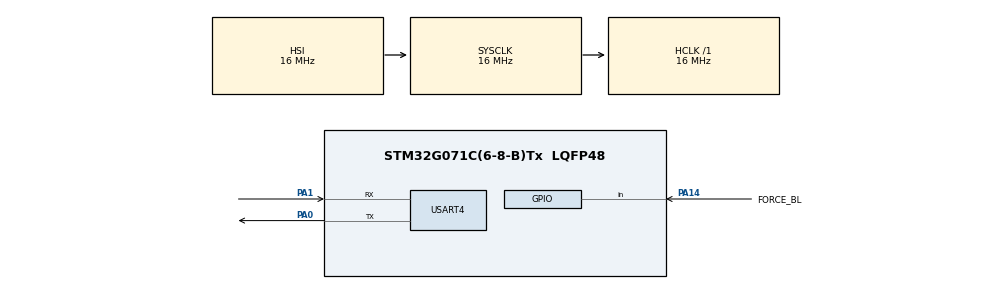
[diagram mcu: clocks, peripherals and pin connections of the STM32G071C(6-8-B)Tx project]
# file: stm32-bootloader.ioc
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Mcu.Family=STM32G0
Mcu.Name=STM32G071C(6-8-B)Tx
Mcu.Package=LQFP48
PA0.Mode=Asynchronous
PA0.Signal=USART4_TX
PA1.Mode=Asynchronous
PA1.Signal=USART4_RX
PA14-BOOT0.GPIO_Label=FORCE_BL
PA14-BOOT0.GPIO_PuPd=GPIO_PULLDOWN
PA14-BOOT0.Signal=GPIO_Input
ProjectManager.HeapSize=0x200
ProjectManager.StackSize=0x400
ProjectManager.TargetToolchain=STM32CubeIDE
RCC.AHBFreq_Value=16000000
RCC.CortexFreq_Value=16000000
RCC.EXTERNAL_CLOCK_VALUE=48000
RCC.HCLKFreq_Value=16000000
RCC.HSE_VALUE=8000000
RCC.HSI_VALUE=16000000
RCC.LSE_VALUE=32768
RCC.SYSCLKFreq_VALUE=16000000
RCC.VCOOutputFreq_Value=128000000
USART4.Parity=PARITY_EVEN
USART4.StopBits=STOPBITS_1
USART4.VirtualMode-Asynchronous=VM_ASYNC
USART4.WordLength=WORDLENGTH_9B
VP_SYS_VS_DBSignals.Mode=DisableDeadBatterySignals
board=custom

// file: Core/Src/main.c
/* USER CODE BEGIN Header */
/**
 ******************************************************************************
 * @file           : main.c
 * @brief          : Main program body
 ******************************************************************************
 * @attention
 *
 * Copyright (c) 2022 STMicroelectronics.
 * All rights reserved.
 *
 * This software is licensed under terms that can be found in the LICENSE file
 * in the root directory of this software component.
 * If no LICENSE file comes with this software, it is provided AS-IS.
 *
 ******************************************************************************
 */
/* USER CODE END Header */
#include "main.h"

/* USER CODE BEGIN Includes */
#include "bootloader.h"

/* USER CODE END Includes */

void SystemClock_Config(void);
static void MX_GPIO_Init(void);
static void MX_USART4_UART_Init(void);
/* USER CODE BEGIN PFP */
static void MX_GPIO_DeInit(void);
/* USER CODE END PFP */

int main(void) {

  /* MCU Configuration--------------------------------------------------------*/

  /* Reset of all peripherals, Initializes the Flash interface and the Systick. */
  HAL_Init();

  /* Configure the system clock */
  SystemClock_Config();

  /* USER CODE BEGIN SysInit */
  uwTick = 0;
  while (HAL_GetTick() < 300)
    ;

  /* USER CODE END SysInit */

  /* Initialize all configured peripherals */
  MX_GPIO_Init();

  /* USER CODE BEGIN 2 */

  uint8_t bl_forced = LL_GPIO_IsInputPinSet(FORCE_BL_GPIO_Port, FORCE_BL_Pin);
  MX_GPIO_DeInit();

  /* USER CODE END 2 */

  /* Infinite loop */
  /* USER CODE BEGIN WHILE */
  if (bl_forced == 0) {
    MX_USART4_UART_Init();
    bootloader_loop(USART4);
  }

  bootloader_start_user_program();

  /* USER CODE END WHILE */

}

void SystemClock_Config(void) {
  RCC_OscInitTypeDef RCC_OscInitStruct = { 0 };
  RCC_ClkInitTypeDef RCC_ClkInitStruct = { 0 };

  /** Configure the main internal regulator output voltage
   */
  HAL_PWREx_ControlVoltageScaling(PWR_REGULATOR_VOLTAGE_SCALE1);
  /** Initializes the RCC Oscillators according to the specified parameters
   * in the RCC_OscInitTypeDef structure.
   */
  RCC_OscInitStruct.OscillatorType = RCC_OSCILLATORTYPE_HSI;
  RCC_OscInitStruct.HSIState = RCC_HSI_ON;
  RCC_OscInitStruct.HSIDiv = RCC_HSI_DIV1;
  RCC_OscInitStruct.HSICalibrationValue = RCC_HSICALIBRATION_DEFAULT;
  RCC_OscInitStruct.PLL.PLLState = RCC_PLL_NONE;
  if (HAL_RCC_OscConfig(&RCC_OscInitStruct) != HAL_OK) {
    Error_Handler();
  }
  /** Initializes the CPU, AHB and APB buses clocks
   */
  RCC_ClkInitStruct.ClockType = RCC_CLOCKTYPE_HCLK | RCC_CLOCKTYPE_SYSCLK | RCC_CLOCKTYPE_PCLK1;
  RCC_ClkInitStruct.SYSCLKSource = RCC_SYSCLKSOURCE_HSI;
  RCC_ClkInitStruct.AHBCLKDivider = RCC_SYSCLK_DIV1;
  RCC_ClkInitStruct.APB1CLKDivider = RCC_HCLK_DIV1;

  if (HAL_RCC_ClockConfig(&RCC_ClkInitStruct, FLASH_LATENCY_0) != HAL_OK) {
    Error_Handler();
  }
}

static void MX_USART4_UART_Init(void) {

  LL_USART_InitTypeDef USART_InitStruct = { 0 };

  LL_GPIO_InitTypeDef GPIO_InitStruct = { 0 };

  /* Peripheral clock enable */
  LL_APB1_GRP1_EnableClock(LL_APB1_GRP1_PERIPH_USART4);

  LL_IOP_GRP1_EnableClock(LL_IOP_GRP1_PERIPH_GPIOA);
  /**USART4 GPIO Configuration
   PA0   ------> USART4_TX
   PA1   ------> USART4_RX
   */
  GPIO_InitStruct.Pin = LL_GPIO_PIN_0;
  GPIO_InitStruct.Mode = LL_GPIO_MODE_ALTERNATE;
  GPIO_InitStruct.Speed = LL_GPIO_SPEED_FREQ_LOW;
  GPIO_InitStruct.OutputType = LL_GPIO_OUTPUT_PUSHPULL;
  GPIO_InitStruct.Pull = LL_GPIO_PULL_NO;
  GPIO_InitStruct.Alternate = LL_GPIO_AF_4;
  LL_GPIO_Init(GPIOA, &GPIO_InitStruct);

  GPIO_InitStruct.Pin = LL_GPIO_PIN_1;
  GPIO_InitStruct.Mode = LL_GPIO_MODE_ALTERNATE;
  GPIO_InitStruct.Speed = LL_GPIO_SPEED_FREQ_LOW;
  GPIO_InitStruct.OutputType = LL_GPIO_OUTPUT_PUSHPULL;
  GPIO_InitStruct.Pull = LL_GPIO_PULL_NO;
  GPIO_InitStruct.Alternate = LL_GPIO_AF_4;
  LL_GPIO_Init(GPIOA, &GPIO_InitStruct);

  USART_InitStruct.PrescalerValue = LL_USART_PRESCALER_DIV1;
  USART_InitStruct.BaudRate = 115200;
  USART_InitStruct.DataWidth = LL_USART_DATAWIDTH_9B;
  USART_InitStruct.StopBits = LL_USART_STOPBITS_1;
  USART_InitStruct.Parity = LL_USART_PARITY_EVEN;
  USART_InitStruct.TransferDirection = LL_USART_DIRECTION_TX_RX;
  USART_InitStruct.HardwareFlowControl = LL_USART_HWCONTROL_NONE;
  USART_InitStruct.OverSampling = LL_USART_OVERSAMPLING_16;
  LL_USART_Init(USART4, &USART_InitStruct);
  LL_USART_ConfigAsyncMode(USART4);

  LL_USART_Enable(USART4);

  /* Polling USART4 initialisation */
  while ((!(LL_USART_IsActiveFlag_TEACK(USART4))) || (!(LL_USART_IsActiveFlag_REACK(USART4)))) {
  }

}

static void MX_GPIO_Init(void) {
  LL_GPIO_InitTypeDef GPIO_InitStruct = { 0 };

  /* GPIO Ports Clock Enable */
  LL_IOP_GRP1_EnableClock(LL_IOP_GRP1_PERIPH_GPIOA);

  /**/
  GPIO_InitStruct.Pin = FORCE_BL_Pin;
  GPIO_InitStruct.Mode = LL_GPIO_MODE_INPUT;
  GPIO_InitStruct.Pull = LL_GPIO_PULL_UP;
  LL_GPIO_Init(FORCE_BL_GPIO_Port, &GPIO_InitStruct);

}

/* USER CODE BEGIN 4 */
static void MX_GPIO_DeInit(void) {
  LL_GPIO_InitTypeDef GPIO_InitStruct = { 0 };

  GPIO_InitStruct.Pin = FORCE_BL_Pin;
  GPIO_InitStruct.Mode = LL_GPIO_MODE_INPUT;
  GPIO_InitStruct.Pull = LL_GPIO_PULL_NO;
  LL_GPIO_Init(FORCE_BL_GPIO_Port, &GPIO_InitStruct);

  LL_IOP_GRP1_DisableClock(LL_IOP_GRP1_PERIPH_GPIOA);
}

/* USER CODE END 4 */

void Error_Handler(void) {
  __disable_irq();
  while (1) {
  }
}
